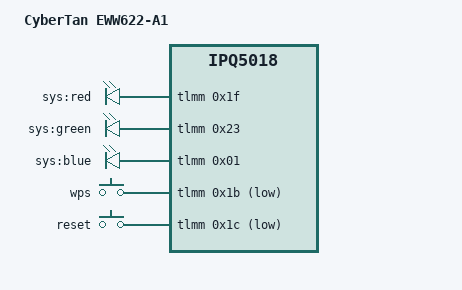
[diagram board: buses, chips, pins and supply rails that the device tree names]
/*
 * Copyright (c) 2018-2020, The Linux Foundation. All rights reserved.
 *
 * Permission to use, copy, modify, and/or distribute this software for any
 * purpose with or without fee is hereby granted, provided that the above
 * copyright notice and this permission notice appear in all copies.
 *
 * THE SOFTWARE IS PROVIDED "AS IS" AND THE AUTHOR DISCLAIMS ALL WARRANTIES
 * WITH REGARD TO THIS SOFTWARE INCLUDING ALL IMPLIED WARRANTIES OF
 * MERCHANTABILITY AND FITNESS. IN NO EVENT SHALL THE AUTHOR BE LIABLE FOR
 * ANY SPECIAL, DIRECT, INDIRECT, OR CONSEQUENTIAL DAMAGES OR ANY DAMAGES
 * WHATSOEVER RESULTING FROM LOSS OF USE, DATA OR PROFITS, WHETHER IN AN
 * ACTION OF CONTRACT, NEGLIGENCE OR OTHER TORTIOUS ACTION, ARISING OUT OF
 * OR IN CONNECTION WITH THE USE OR PERFORMANCE OF THIS SOFTWARE.
 */

#include "../../../arm64/boot/dts/qcom/qcom-ipq5018-mp03.1.dts"

/ {
	model = "CyberTan EWW622-A1";
	compatible = "cybertan,eww622-a1", "qcom,ipq5018";

	pmuv8: pmu {
		compatible = "arm,cortex-a7-pmu";
	};

	soc {
		gpio_leds {
			pinctrl-0 = <&leds_pins>;
			compatible = "gpio-leds";
			pinctrl-names = "default";

			led@31 {
				label = "sys:red";
				gpios = <&tlmm 0x1f 0x00>;
			};

			led@35 {
				label = "sys:green";
				gpios = <&tlmm 0x23 0x00>;
			};

			led@1 {
				label = "sys:blue";
				gpios = <&tlmm 0x01 0x00>;
			};
		};

		gpio_keys {
			pinctrl-0 = <&keys_pins>;
			compatible = "gpio-keys";
			pinctrl-names = "default";

			button@1 {
				label = "wps";
				gpios = <&tlmm 0x1b 0x01>;
				linux,input-type = <0x01>;
				debounce-interval = <0x3c>;
				linux,code = <0x211>;
			};

			button@2 {
				label = "reset";
				gpios = <&tlmm 0x1c 0x01>;
				linux,input-type = <1>;
				debounce-interval = <0x3c>;
				linux,code = <KEY_RESTART>;
			};
		};
	};
};

&qpic_pins {
	keys_pins: keys_pins {
		wps {
			pins = "gpio27";
			function = "gpio";
			drive-strength = <8>;
			bias-pull-down;
		};
		reset {
			pins = "gpio28";
			function = "gpio";
			drive-strength = <8>;
			bias-pull-down;
		};
	};

	leds_pins: leds_pins {
		led_red {
			pins = "gpio31";
			function = "gpio";
			drive-strength = <8>;
			bias-pull-down;
		};
		led_green {
			pins = "gpio35";
			function = "gpio";
			drive-strength = <8>;
			bias-pull-down;
		};
		led_blue {
			pins = "gpio1";
			function = "gpio";
			drive-strength = <8>;
			bias-pull-down;
		};
	};



